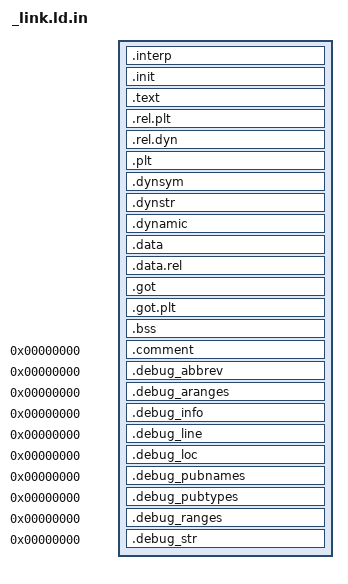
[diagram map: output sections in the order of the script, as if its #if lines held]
STARTUP(LIBC_PREFIX/arch/UARCH/src/entry.o)
ENTRY(__entry)

PHDRS {
        text PT_LOAD FLAGS(5);
	interp PT_INTERP;
	data PT_LOAD FLAGS(6);
	dynamic PT_DYNAMIC;
}

SECTIONS {
	. = 0x1000 + SIZEOF_HEADERS;

	.interp : {
		*(.interp);
	} :interp

	.init : {
		*(.init);
	} :text
	.text : {
		*(.text);
		*(.text.*);
		*(.rodata*);
	} :text

	.rel.plt : {
		*(.rel.plt);
	}
	/* 
	 *.rel.dyn MUST FOLLOW IMMEDIATELY after .rel.plt 
	 * without alignment gap or DT_REL will be broken
	 */
	.rel.dyn : {
		*(.rel.*);
	} :text

	.plt : {
		*(.plt);
	} :text

	.dynsym : {
		*(.dynsym);
	} :text

	.dynstr : {
		*(.dynstr);
	} :text

	. = . + 0x1000;

	.dynamic : {
		*(.dynamic);
	} :data :dynamic

	.data : {
		*(.data);
	} :data

	.data.rel : {
                *(.data.rel);
	} :data

	.got : {
                *(.got);
	} :data
	.got.plt : {
                *(.got.plt);
	} :data

	.bss : {
                *(COMMON);
                *(.bss);
	} :data

/*	.tdata : {
		_tdata_start = .;
		*(.tdata);
		*(.gnu.linkonce.tb.*);
		_tdata_end = .;
		_tbss_start = .;
		*(.tbss);
		_tbss_end = .;
	} :data
	_tls_alignment = ALIGNOF(.tdata);
*/

#ifdef CONFIG_LINE_DEBUG
	.comment 0 : { *(.comment); } :debug
	.debug_abbrev 0 : { *(.debug_abbrev); } :debug
	.debug_aranges 0 : { *(.debug_aranges); } :debug
	.debug_info 0 : { *(.debug_info); } :debug
	.debug_line 0 : { *(.debug_line); } :debug
	.debug_loc 0 : { *(.debug_loc); } :debug
	.debug_pubnames 0 : { *(.debug_pubnames); } :debug
	.debug_pubtypes 0 : { *(.debug_pubtypes); } :debug
	.debug_ranges 0 : { *(.debug_ranges); } :debug
	.debug_str 0 : { *(.debug_str); } :debug
#endif
	/DISCARD/ : {
		*(.comment);
	}

	. = ALIGN(0x1000);
	_heap = .;
}
